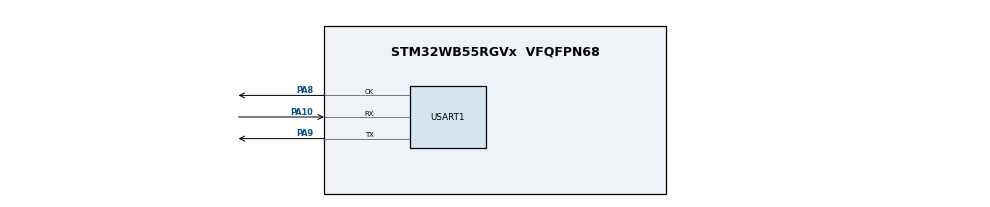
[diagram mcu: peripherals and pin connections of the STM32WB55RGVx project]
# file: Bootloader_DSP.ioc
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Mcu.Family=STM32WB
Mcu.Name=STM32WB55RGVx
Mcu.Package=VFQFPN68
NVIC.PriorityGroup=NVIC_PRIORITYGROUP_4
NVIC.USART1_IRQn=true\:0\:0\:false\:false\:true\:true\:true\:true
OSC_IN.Mode=HSE-External-Oscillator
OSC_IN.Signal=RCC_OSC_IN
OSC_OUT.Mode=HSE-External-Oscillator
OSC_OUT.Signal=RCC_OSC_OUT
PA10.Mode=Synchronous
PA10.Signal=USART1_RX
PA8.Mode=Synchronous
PA8.Signal=USART1_CK
PA9.Mode=Synchronous
PA9.Signal=USART1_TX
PC14-OSC32_IN.Mode=LSE-External-Oscillator
PC14-OSC32_IN.Signal=RCC_OSC32_IN
PC15-OSC32_OUT.Mode=LSE-External-Oscillator
PC15-OSC32_OUT.Signal=RCC_OSC32_OUT
ProjectManager.HeapSize=0x200
ProjectManager.StackSize=0x400
ProjectManager.TargetToolchain=STM32CubeIDE
RCC.APB3Freq_Value=4000000
RCC.HSE_VALUE=8000000
RCC.HSI48_VALUE=48000000
RCC.HSI_VALUE=16000000
RCC.VCOOutputFreq_Value=32000000
USART1.VirtualMode-Synchronous=VM_SYNC
VP_MEMORYMAP_VS_MEMORYMAP.Mode=CurAppReg
board=custom

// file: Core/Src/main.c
/* USER CODE BEGIN Header */
/**
  ******************************************************************************
  * @file           : main.c
  * @brief          : Main program body
  ******************************************************************************
  * @attention
  *
  * Copyright (c) 2026 STMicroelectronics.
  * All rights reserved.
  *
  * This software is licensed under terms that can be found in the LICENSE file
  * in the root directory of this software component.
  * If no LICENSE file comes with this software, it is provided AS-IS.
  *
  ******************************************************************************
  */
/* USER CODE END Header */
#include "main.h"
#include "bootloader.h"

USART_HandleTypeDef husart1;

void SystemClock_Config(void);
void PeriphCommonClock_Config(void);
static void MX_GPIO_Init(void);
static void MX_USART1_Init(void);

int main(void)
{

  /* MCU Configuration--------------------------------------------------------*/

  /* Reset of all peripherals, Initializes the Flash interface and the Systick. */
  HAL_Init();

  /* Configure the system clock */
  SystemClock_Config();

  /* Configure the peripherals common clocks */
  PeriphCommonClock_Config();

  /* Initialize all configured peripherals */
  MX_GPIO_Init();
  MX_USART1_Init();
  /* USER CODE BEGIN 2 */
  Bootloader_Run();
  /* USER CODE END 2 */

  /* Infinite loop */
  while (1)
  {

  }
}

void SystemClock_Config(void)
{
  RCC_OscInitTypeDef RCC_OscInitStruct = {0};
  RCC_ClkInitTypeDef RCC_ClkInitStruct = {0};

  /** Configure the main internal regulator output voltage
  */
  __HAL_PWR_VOLTAGESCALING_CONFIG(PWR_REGULATOR_VOLTAGE_SCALE1);

  /** Initializes the RCC Oscillators according to the specified parameters
  * in the RCC_OscInitTypeDef structure.
  */
  RCC_OscInitStruct.OscillatorType = RCC_OSCILLATORTYPE_HSI|RCC_OSCILLATORTYPE_HSE
                              |RCC_OSCILLATORTYPE_MSI;
  RCC_OscInitStruct.HSEState = RCC_HSE_ON;
  RCC_OscInitStruct.HSIState = RCC_HSI_ON;
  RCC_OscInitStruct.MSIState = RCC_MSI_ON;
  RCC_OscInitStruct.HSICalibrationValue = RCC_HSICALIBRATION_DEFAULT;
  RCC_OscInitStruct.MSICalibrationValue = RCC_MSICALIBRATION_DEFAULT;
  RCC_OscInitStruct.MSIClockRange = RCC_MSIRANGE_6;
  RCC_OscInitStruct.PLL.PLLState = RCC_PLL_NONE;
  if (HAL_RCC_OscConfig(&RCC_OscInitStruct) != HAL_OK)
  {
    Error_Handler();
  }

  /** Configure the SYSCLKSource, HCLK, PCLK1 and PCLK2 clocks dividers
  */
  RCC_ClkInitStruct.ClockType = RCC_CLOCKTYPE_HCLK4|RCC_CLOCKTYPE_HCLK2
                              |RCC_CLOCKTYPE_HCLK|RCC_CLOCKTYPE_SYSCLK
                              |RCC_CLOCKTYPE_PCLK1|RCC_CLOCKTYPE_PCLK2;
  RCC_ClkInitStruct.SYSCLKSource = RCC_SYSCLKSOURCE_MSI;
  RCC_ClkInitStruct.AHBCLKDivider = RCC_SYSCLK_DIV1;
  RCC_ClkInitStruct.APB1CLKDivider = RCC_HCLK_DIV1;
  RCC_ClkInitStruct.APB2CLKDivider = RCC_HCLK_DIV1;
  RCC_ClkInitStruct.AHBCLK2Divider = RCC_SYSCLK_DIV1;
  RCC_ClkInitStruct.AHBCLK4Divider = RCC_SYSCLK_DIV1;

  if (HAL_RCC_ClockConfig(&RCC_ClkInitStruct, FLASH_LATENCY_0) != HAL_OK)
  {
    Error_Handler();
  }
}

void PeriphCommonClock_Config(void)
{
  RCC_PeriphCLKInitTypeDef PeriphClkInitStruct = {0};

  /** Initializes the peripherals clock
  */
  PeriphClkInitStruct.PeriphClockSelection = RCC_PERIPHCLK_SMPS;
  PeriphClkInitStruct.SmpsClockSelection = RCC_SMPSCLKSOURCE_HSI;
  PeriphClkInitStruct.SmpsDivSelection = RCC_SMPSCLKDIV_RANGE1;

  if (HAL_RCCEx_PeriphCLKConfig(&PeriphClkInitStruct) != HAL_OK)
  {
    Error_Handler();
  }
}

static void MX_USART1_Init(void)
{

  husart1.Instance = USART1;
  husart1.Init.BaudRate = 115200;
  husart1.Init.WordLength = USART_WORDLENGTH_8B;
  husart1.Init.StopBits = USART_STOPBITS_1;
  husart1.Init.Parity = USART_PARITY_NONE;
  husart1.Init.Mode = USART_MODE_TX_RX;
  husart1.Init.CLKPolarity = USART_POLARITY_LOW;
  husart1.Init.CLKPhase = USART_PHASE_1EDGE;
  husart1.Init.CLKLastBit = USART_LASTBIT_DISABLE;
  husart1.Init.ClockPrescaler = USART_PRESCALER_DIV1;
  husart1.SlaveMode = USART_SLAVEMODE_DISABLE;
  if (HAL_USART_Init(&husart1) != HAL_OK)
  {
    Error_Handler();
  }
  if (HAL_USARTEx_SetTxFifoThreshold(&husart1, USART_TXFIFO_THRESHOLD_1_8) != HAL_OK)
  {
    Error_Handler();
  }
  if (HAL_USARTEx_SetRxFifoThreshold(&husart1, USART_RXFIFO_THRESHOLD_1_8) != HAL_OK)
  {
    Error_Handler();
  }
  if (HAL_USARTEx_DisableFifoMode(&husart1) != HAL_OK)
  {
    Error_Handler();
  }

}

static void MX_GPIO_Init(void)
{

  /* GPIO Ports Clock Enable */
  __HAL_RCC_GPIOC_CLK_ENABLE();
  __HAL_RCC_GPIOA_CLK_ENABLE();

}

void Error_Handler(void)
{
  __disable_irq();
  while (1)
  {
  }
}
